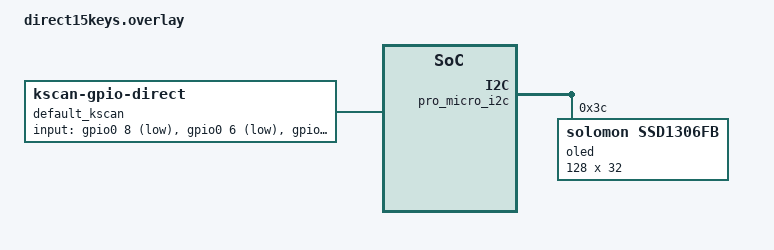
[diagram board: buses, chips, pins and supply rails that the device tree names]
/ {
	chosen {
		zmk,kscan = &default_kscan;
		zephyr,display = &oled;
	};

	default_kscan: kscan {
		compatible = "zmk,kscan-gpio-direct";
		wakeup-source;

		/* switches are connected to the GND if pressed --> pull up and low active */
		input-gpios
            = <&gpio0 8  (GPIO_ACTIVE_LOW | GPIO_PULL_UP)>  /* D0 */
			, <&gpio0 6  (GPIO_ACTIVE_LOW | GPIO_PULL_UP)>	/* D1 */
			, <&gpio0 17 (GPIO_ACTIVE_LOW | GPIO_PULL_UP)> 	/* D2 */
			, <&gpio0 20 (GPIO_ACTIVE_LOW | GPIO_PULL_UP)>	/* D4/A6 */
			, <&gpio0 22 (GPIO_ACTIVE_LOW | GPIO_PULL_UP)>	/* D5  */
            , <&gpio0 24 (GPIO_ACTIVE_LOW | GPIO_PULL_UP)>	/* D6/A7 */
			, <&gpio1 0  (GPIO_ACTIVE_LOW | GPIO_PULL_UP)>
			, <&gpio0 11 (GPIO_ACTIVE_LOW | GPIO_PULL_UP)>
			, <&gpio1 4  (GPIO_ACTIVE_LOW | GPIO_PULL_UP)>
			, <&gpio1 6  (GPIO_ACTIVE_LOW | GPIO_PULL_UP)>
            , <&gpio0 9  (GPIO_ACTIVE_LOW | GPIO_PULL_UP)>
			, <&gpio0 10 (GPIO_ACTIVE_LOW | GPIO_PULL_UP)>
            , <&gpio1 11 (GPIO_ACTIVE_LOW | GPIO_PULL_UP)>
			, <&gpio1 13 (GPIO_ACTIVE_LOW | GPIO_PULL_UP)>
            , <&gpio1 15 (GPIO_ACTIVE_LOW | GPIO_PULL_UP)>
			;

	};


};

&pro_micro_i2c {
    status = "okay";

    oled: ssd1306@3c {
        compatible = "solomon,ssd1306fb";
        reg = <0x3c>;
        width = <128>;
        height = <32>;
        segment-offset = <0>;
        page-offset = <0>;
        display-offset = <0>;
        multiplex-ratio = <31>;
        segment-remap;
        com-invdir;
        com-sequential;
        inversion-on;
        prechargep = <0x22>;
    };
};

